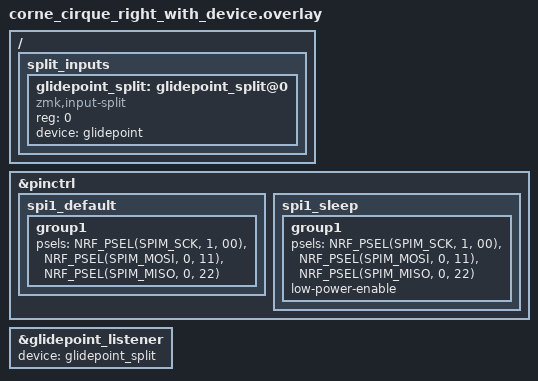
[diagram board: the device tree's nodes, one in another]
#include "corne_cirque_right_shared.dtsi"

&pinctrl {
    /* configuration for spi1 device, default state */
    spi1_default: spi1_default {
        /* node name is arbitrary */
        group1 {
            psels = <NRF_PSEL(SPIM_SCK,  1, 00)>,
                    <NRF_PSEL(SPIM_MOSI, 0, 11)>,
                    <NRF_PSEL(SPIM_MISO, 0, 22)>;
        };
    };

    /* configuration for spi1 device, sleep state */
    spi1_sleep: spi1_sleep {
        group1 {
            psels = <NRF_PSEL(SPIM_SCK, 1, 00)>,
                    <NRF_PSEL(SPIM_MOSI, 0, 11)>,
                    <NRF_PSEL(SPIM_MISO, 0, 22)>;
            low-power-enable;
        };
    };

};


/ {
    split_inputs {
        #address-cells = <1>;
        #size-cells = <0>;

        glidepoint_split: glidepoint_split@0 {
            compatible = "zmk,input-split";
            reg = <0>;
            device = <&glidepoint>;
        };
    };
};

&glidepoint_listener {
    device = <&glidepoint_split>;
};
